# APM32F00x register map
File version: 1.0
CPU: CM0+ r0p0, little endian, no MPU, no FPU, 4 interrupt priority bits
Registers are 32-bit, read-write, reset 0x0 unless marked. A register's access mark holds for its fields unless they carry their own. Offsets are from the block's base; [hi:lo] are bit positions; {n}, {i} and the like mark numbered series.

## UART1 — Universal asynchronous receiver transmitter
Base 0x40003400
Same registers: UART2 0x40001400, UART3 0x40004800
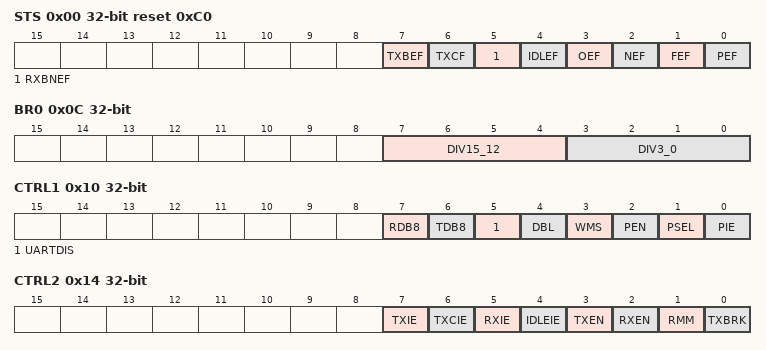
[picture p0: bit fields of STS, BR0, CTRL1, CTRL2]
0x00 STS access per field reset 0xC0 — Status register
  [7] TXBEF ro — Transmit data register empty
  [6] TXCF rw — Transmission complete
  [5] RXBNEF rw — Read data register not empty
  [4] IDLEF ro — IDLE line detected
  [3] OEF ro — Overrun error
  [2] NEF ro — Noise error flag
  [1] FEF ro — Framing error
  [0] PEF ro — Parity error
0x04 DATA
  [8:0] DATA — Data value
0x08 BR1 — Baud rate register 1
  [7:0] DIV11_4 — LSB mantissa of UARTxDIV [7:0] mask
0x0C BR0 — Baud rate register 2
  [7:4] DIV15_12 — MSB mantissa of UARTxDIV [15:12] mask
  [3:0] DIV3_0 — Fraction bits of UARTxDIV [3:0] mask
0x10 CTRL1 — Control register 1
  [7] RDB8 — Receive Data bit 8
  [6] TDB8 — Transmit data bit 8
  [5] UARTDIS — UARTx Disable (for low power consumption)
  [4] DBL — Word length mask
  [3] WMS — Wake-up method mask
  [2] PEN — Parity Control Enable mask
  [1] PSEL — UARTx Parity Selection
  [0] PIE — UARTx Parity Interrupt Enable mask
0x14 CTRL2 — Control register 2
  [7] TXIE, [6] TXCIE, [5] RXIE, [4] IDLEIE, [3] TXEN, [2] RXEN, [1] RMM, [0] TXBRK
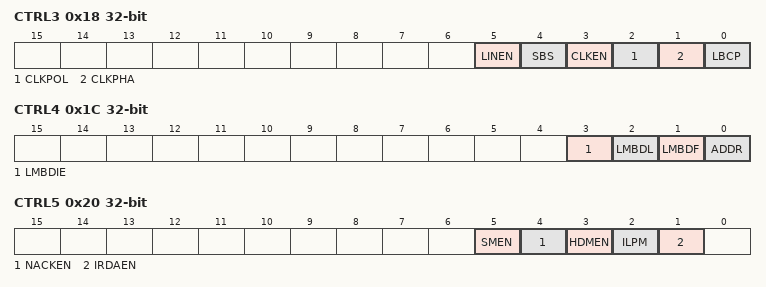
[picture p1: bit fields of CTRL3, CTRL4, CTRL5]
0x18 CTRL3 — Control register 3
  [5] LINEN, [4] SBS, [3] CLKEN, [2] CLKPOL, [1] CLKPHA, [0] LBCP
0x1C CTRL4 — Control register 4
  [3] LMBDIE, [2] LMBDL, [1] LMBDF, [0] ADDR
0x20 CTRL5 — Control register 5
  [5] SMEN, [4] NACKEN, [3] HDMEN, [2] ILPM, [1] IRDAEN
0x24 GTS — Guard time and register
  [15:8] GTS
0x28 DIV — UART1 prescaler register
  [15:8] DIV
0x2C SW — UART2/USART3 switch register
  [0] SW
0x30 IOSW2 — UART3 IO switch register
  [0] SW

## I2C — Inter-integrated circuit interface
Base 0x40003000
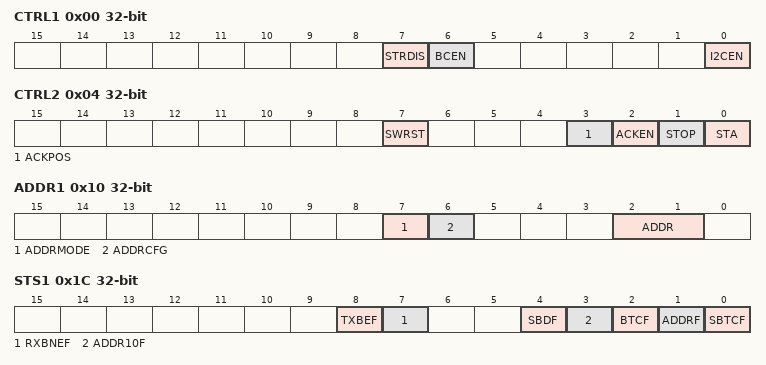
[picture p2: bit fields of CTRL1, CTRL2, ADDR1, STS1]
0x00 CTRL1 — Control register 1
  [7] STRDIS, [6] BCEN, [0] I2CEN
0x04 CTRL2 — Control register 2
  [7] SWRST, [3] ACKPOS, [2] ACKEN, [1] STOP, [0] STA
0x08 CLKFREQ — Frequency Control register
  [5:0] FREQ
0x0C ADDR0 — Slave address register 0
  [7:0] ADDR0
0x10 ADDR1 — Slave address register 1
  [7] ADDRMODE, [6] ADDRCFG, [2:1] ADDR
0x18 DATA
  [7:0] DATA
0x1C STS1 ro — Status register 1
  [8] TXBEF, [7] RXBNEF, [4] SBDF, [3] ADDR10F, [2] BTCF, [1] ADDRF, [0] SBTCF
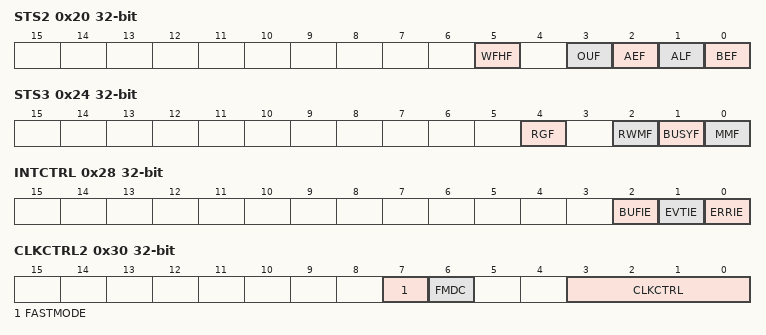
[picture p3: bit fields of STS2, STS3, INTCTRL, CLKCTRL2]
0x20 STS2 ro — Status register 2
  [5] WFHF, [3] OUF, [2] AEF, [1] ALF, [0] BEF
0x24 STS3 ro — Status register 3
  [4] RGF, [2] RWMF, [1] BUSYF, [0] MMF
0x28 INTCTRL — Interrupt control register
  [2] BUFIE, [1] EVTIE, [0] ERRIE
0x2C CLKCTRL1 — Clock control register 1
  [7:0] CLKCTRL
0x30 CLKCTRL2 — Clock control register 2
  [7] FASTMODE, [6] FMDC, [3:0] CLKCTRL
0x34 MRT reset 0x2 — Max Rise time register
  [5:0] MRT

## TMR2 — 16-bit timer
Base 0x40003C00
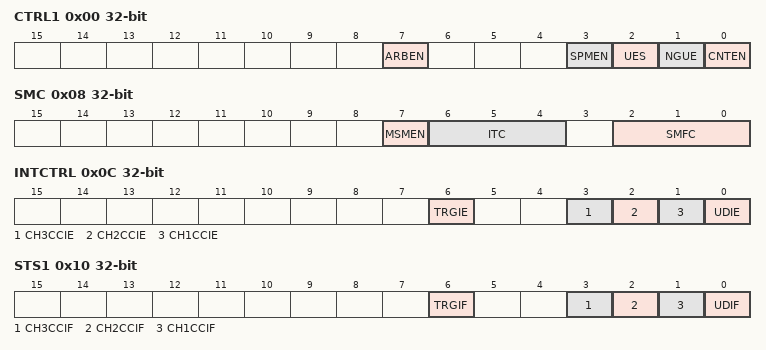
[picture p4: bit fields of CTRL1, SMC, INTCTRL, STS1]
0x00 CTRL1 — control register 1
  [7] ARBEN — Auto-Reload Preload Enable mask.
  [3] SPMEN — One Pulse Mode mask.
  [2] UES — Update Request Source mask.
  [1] NGUE — Update DIsable mask.
  [0] CNTEN — Counter Enable mask.
0x04 CTRL2 — control register 2
  [6:4] MMFC — Capture/Compare Preloaded Control mask.
0x08 SMC — Synchro mode control register
  [7] MSMEN — Slave Mode Selection mask.
  [6:4] ITC — Trigger Selection mask.
  [2:0] SMFC — Master/Slave Mode mask.
0x0C INTCTRL — interrupt enable register
  [6] TRGIE — Trigger Interrupt Enable mask.
  [3] CH3CCIE — Capture/Compare 3 Interrupt Enable mask.
  [2] CH2CCIE — Capture/Compare 2 Interrupt Enable mask.
  [1] CH1CCIE — Capture/Compare 1 Interrupt Enable mask.
  [0] UDIE — Update Interrupt Enable mask.
0x10 STS1 — status register 1
  [6] TRGIF — Trigger Interrupt Flag mask.
  [3] CH3CCIF — Capture/Compare 3 Interrupt Flag mask.
  [2] CH2CCIF — Capture/Compare 2 Interrupt Flag mask.
  [1] CH1CCIF — Capture/Compare 1 Interrupt Flag mask.
  [0] UDIF — Update Interrupt Flag mask.
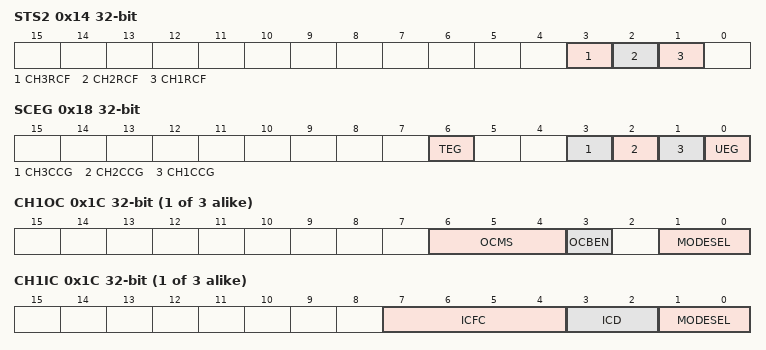
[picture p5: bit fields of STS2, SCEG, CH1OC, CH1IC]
0x14 STS2 — status register 2
  [3] CH3RCF — Capture/Compare 3 Overcapture Flag mask.
  [2] CH2RCF — Capture/Compare 2 Overcapture Flag mask.
  [1] CH1RCF — Capture/Compare 1 Overcapture Flag mask.
0x18 SCEG write — event generation register
  [6] TEG — Trigger Generation mask.
  [3] CH3CCG — Capture/Compare 3 Generation mask.
  [2] CH2CCG — Capture/Compare 2 Generation mask.
  [1] CH1CCG — Capture/Compare 1 Generation mask.
  [0] UEG — Update Generation mask.
{0x18+4i} CH{i}OC (i=1..3) — capture/compare mode register {i} (output mode)
  [6:4] OCMS — Output Compare {i} Mode mask.
  [3] OCBEN — Output Compare {i} Preload Enable mask.
  [1:0] MODESEL — Capture/Compare {i} Selection mask.
{0x18+4i} CH{i}IC (alternate view of CH{i}OC) (i=1..3) — capture/compare mode register {i} (input mode)
  [7:4] ICFC — Input capture {i} filter
  [3:2] ICD — Input capture {i} prescaler
  [1:0] MODESEL — Capture/Compare {i} Selection mask.
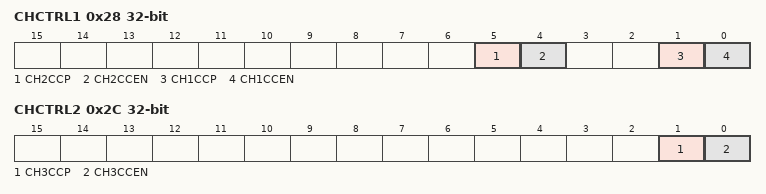
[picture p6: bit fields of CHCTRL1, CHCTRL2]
0x28 CHCTRL1 — Channel control register 1
  [5] CH2CCP — Capture/Compare 2 output Polarity mask.
  [4] CH2CCEN — Capture/Compare 2 output enable mask.
  [1] CH1CCP — Capture/Compare 1 output Polarity mask.
  [0] CH1CCEN — Capture/Compare 1 output enable mask.
0x2C CHCTRL2 — Channel control register 2
  [1] CH3CCP — Capture/Compare 3 output Polarity mask.
  [0] CH3CCEN — Capture/Compare 3 output enable mask.
0x30 CNT1 — Count register 1
  [7:0] CNT — Counter Value (MSB) mask.
0x34 CNT0 — Count register 0
  [7:0] CNT — Counter Value (LSB) mask.
0x38 DIV — divider register
  [3:0] DIV — Prescaler Value mask.
0x3C AUTORLD1 — Auto reload register 1
  [7:0] RELOAD — Autoreload Value (MSB) mask.
0x40 AUTORLD0 — Auto reload register 0
  [7:0] ARR — Autoreload Value (LSB) mask.
{0x3C+8i} CH{i}CC1 (i=1..3) — channel {i} compare/capture register 1
  [7:0] CC — Capture/Compare {i} Value (MSB) mask.
{0x40+8i} CH{i}CC0 (i=1..3) — channel {i} compare/capture register 0
  [7:0] CC — Capture/Compare {i} Value (LSB) mask.
